# STM32WB55xx register map
File version: 1.0
Registers are 32-bit, read-write, reset 0x0 unless marked. A register's access mark holds for its fields unless they carry their own. Offsets are from the block's base; [hi:lo] are bit positions; {n}, {i} and the like mark numbered series; 'fields as' and 'values as' point back to an identical list.

## RCC — Reset and Clock Control
Base 0x58000000
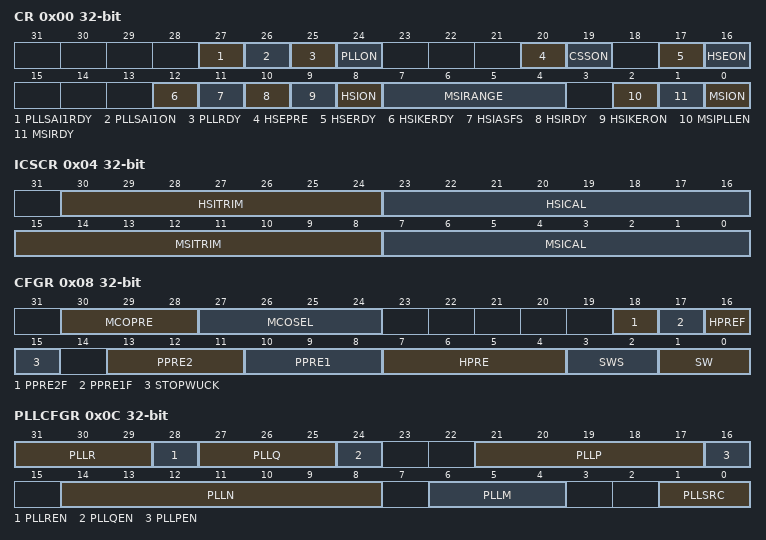
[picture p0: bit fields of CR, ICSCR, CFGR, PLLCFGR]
0x00 CR — RCC clock Control Register
  [27] PLLSAI1RDY — SAI1 PLL ready
  [26] PLLSAI1ON — SAI1 PLL enable
  [25] PLLRDY — System PLL clock ready
  [24] PLLON — System PLL clock enable
  [20] HSEPRE — HSE sysclk prescaler
  [19] CSSON — HSE Clock Security System enable
  [17] HSERDY — External High Speed oscillator (HSE) clock ready
  [16] HSEON — External High Speed oscillator (HSE) clock enable
  [12] HSIKERDY — Internal High Speed oscillator (HSI16) clock enable for some IPs Kernel ready flag
  [11] HSIASFS — HSI16 Automatic Start from Stop
  [10] HSIRDY — Internal High Speed oscillator (HSI16) clock ready flag
  [9] HSIKERON — Internal High Speed oscillator (HSI16) clock enable for some IPs Kernel
  [8] HSION — Internal High Speed oscillator (HSI16) clock enable
  [7:4] MSIRANGE — Internal Multi Speed oscillator (MSI) clock Range
    0=MSI = 100 KHz; 1=MSI = 200 KHz; 2=MSI = 400 KHz; 3=MSI = 800 KHz; 4=MSI = 1 MHz; 5=MSI = 2 MHz; 6=MSI = 4 MHz; 7=MSI = 8 MHz; 8=MSI = 16 MHz; 9=MSI = 24 MHz; 10=MSI = 32 MHz; 11=MSI = 48 MHz
  [2] MSIPLLEN — Internal Multi Speed oscillator (MSI) PLL enable
  [1] MSIRDY — Internal Multi Speed oscillator (MSI) clock ready flag
  [0] MSION — Internal Multi Speed oscillator (MSI) clock enable
0x04 ICSCR — RCC Internal Clock Sources Calibration Register
  [30:24] HSITRIM — HSITRIM[6:0] bits
  [23:16] HSICAL — HSICAL[7:0] bits
  [15:8] MSITRIM — MSITRIM[7:0] bits
  [7:0] MSICAL — MSICAL[7:0] bits
0x08 CFGR — RCC Clocks Configuration Register
  [30:28] MCOPRE — MCO prescaler
  [27:24] MCOSEL — MCOSEL [3:0] bits (Clock output selection)
  [18] PPRE2F — APB2 prescaler flag
  [17] PPRE1F — CPU1 APB1 prescaler flag
  [16] HPREF — AHB prescaler flag
  [15] STOPWUCK — Wake Up from stop and CSS backup clock selection
    0=MSI (MSI selection after wake-up from STOP); 1=HSI (HSI selection after wake-up from STOP)
  [13:11] PPRE2 — PRE2[2:0] bits (APB2 prescaler)
    0=DIV_1 (HCLK1 not divided); 4=DIV_2 (HCLK1 divided by 2); 5=DIV_4 (HCLK1 divided by 4); 6=DIV_8 (HCLK1 divided by 8); 7=DIV_16 (HCLK1 divided by 16)
  [10:8] PPRE1 — PRE1[2:0] bits (APB1 prescaler)
    values as PPRE2
  [7:4] HPRE — HPRE[3:0] bits (AHB prescaler)
    0=DIV_1 (SYSCLK not divided); 8=DIV_2 (SYSCLK divided by 2); 1=DIV_3 (SYSCLK divided by 3); 9=DIV_4 (SYSCLK divided by 4); 2=DIV_5 (SYSCLK divided by 5); 5=DIV_6 (SYSCLK divided by 6); 10=DIV_8 (SYSCLK divided by 8); 6=DIV_10 (SYSCLK divided by 10); 11=DIV_16 (SYSCLK divided by 16); 7=DIV_32 (SYSCLK divided by 32); 12=DIV_64 (SYSCLK divided by 64); 13=DIV_128 (SYSCLK divided by 128); 14=DIV_256 (SYSCLK divided by 256); 15=DIV_512 (SYSCLK divided by 512)
  [3:2] SWS — SWS[1:0] bits (System Clock Switch Status)
    0=MSI (MSI used as system clock); 1=HSI (HSI used as system clock); 2=HSE (HSE used as system clock); 3=PLL (PLL used as system clock)
  [1:0] SW — SW[1:0] bits (System clock Switch)
    0=MSI (MSI selection as system clock); 1=HSI (HSI selection as system clock); 2=HSE (HSE selection as system clock); 3=PLL (PLL selection as system clock)
0x0C PLLCFGR — RCC System PLL configuration Register
  [31:29] PLLR
    {v}=DIV_{v+1} (Main PLL division factor for PLLCLK (system clock) by {v+1}) (v=1..7)
  [28] PLLREN
  [27:25] PLLQ
    {v}=DIV_{v+1} (Main PLL division factor for PLLQ output by {v+1}) (v=1..7)
  [24] PLLQEN
  [21:17] PLLP
    {v}=DIV_{v+1} (Main PLL division factor for PLLP output by {v+1}) (v=1..31)
  [16] PLLPEN
  [14:8] PLLN
  [6:4] PLLM
    {v}=DIV_{v+1} (PLL and PLLSAI1 division factor by {v+1}) (v=0..7)
  [1:0] PLLSRC
    1=MSI (MSI clock selected as PLL entry clock source); 2=HSI (HSI clock selected as PLL entry clock source); 3=HSE (HSE clock selected as PLL entry clock source); 0=NONE (No clock)
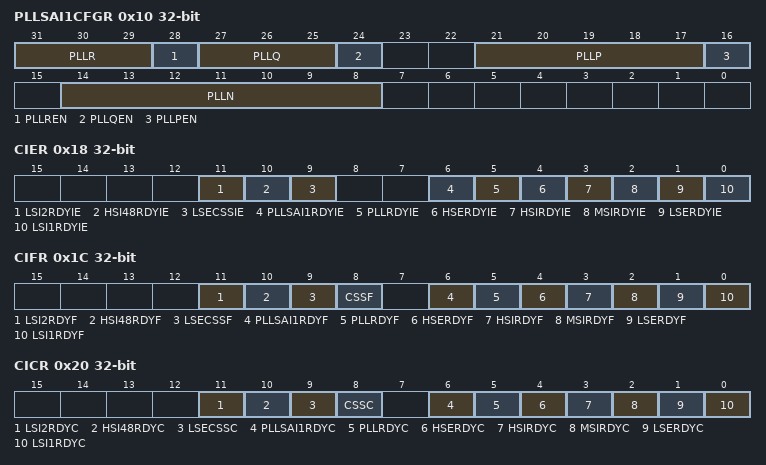
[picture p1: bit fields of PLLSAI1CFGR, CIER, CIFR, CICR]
0x10 PLLSAI1CFGR — RCC PLL SAI1 configuration Register
  [31:29] PLLR
    {v}=DIV_{v+1} (PLLSAI1 division factor for PLLSAI1R output by {v+1}) (v=1..7)
  [28] PLLREN
  [27:25] PLLQ
    {v}=DIV_{v+1} (PLLSAI1 division factor for PLLSAI1Q output by {v+1}) (v=1..7)
  [24] PLLQEN
  [21:17] PLLP
    values as PLLCFGR.PLLP
  [16] PLLPEN
  [14:8] PLLN
0x18 CIER — RCC Clock Interrupt Enable Register
  [11] LSI2RDYIE, [10] HSI48RDYIE, [9] LSECSSIE, [6] PLLSAI1RDYIE, [5] PLLRDYIE, [4] HSERDYIE, [3] HSIRDYIE, [2] MSIRDYIE, [1] LSERDYIE, [0] LSI1RDYIE
0x1C CIFR — RCC Clock Interrupt Flag Register
  [11] LSI2RDYF, [10] HSI48RDYF, [9] LSECSSF, [8] CSSF, [6] PLLSAI1RDYF, [5] PLLRDYF, [4] HSERDYF, [3] HSIRDYF, [2] MSIRDYF, [1] LSERDYF, [0] LSI1RDYF
0x20 CICR — RCC Clock Interrupt Clear Register
  [11] LSI2RDYC, [10] HSI48RDYC, [9] LSECSSC, [8] CSSC, [6] PLLSAI1RDYC, [5] PLLRDYC, [4] HSERDYC, [3] HSIRDYC, [2] MSIRDYC, [1] LSERDYC, [0] LSI1RDYC
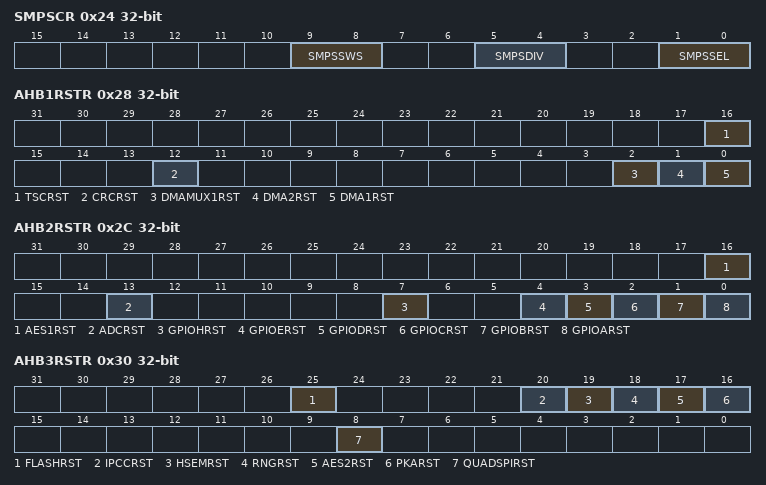
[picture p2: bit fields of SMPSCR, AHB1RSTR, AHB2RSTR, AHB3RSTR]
0x24 SMPSCR — RCC SMPS step-down converter control register
  [9:8] SMPSSWS
    0=HSI (HSI used as SMPS clock); 1=MSI (MSI used as SMPS clock); 2=HSE (HSE used as SMPS clock); 3=NO_CLOCK (No Clock used as SMPS clock)
  [5:4] SMPSDIV
    {v}=DIV_{v} (SMPS clock division {v}) (v=0..3)
  [1:0] SMPSSEL
    0=HSI (HSI selection as SMPS clock); 1=MSI (MSI selection as SMPS clock); 2=HSE (HSE selection as SMPS clock)
0x28 AHB1RSTR — RCC AHB1 peripheral reset register
  [16] TSCRST, [12] CRCRST, [2] DMAMUX1RST, [1] DMA2RST, [0] DMA1RST
0x2C AHB2RSTR — RCC AHB2 peripheral reset register
  [16] AES1RST, [13] ADCRST, [7] GPIOHRST, [4] GPIOERST, [3] GPIODRST, [2] GPIOCRST, [1] GPIOBRST, [0] GPIOARST
0x30 AHB3RSTR — RCC AHB3 & AHB4 peripheral reset register
  [25] FLASHRST, [20] IPCCRST, [19] HSEMRST, [18] RNGRST, [17] AES2RST, [16] PKARST, [8] QUADSPIRST
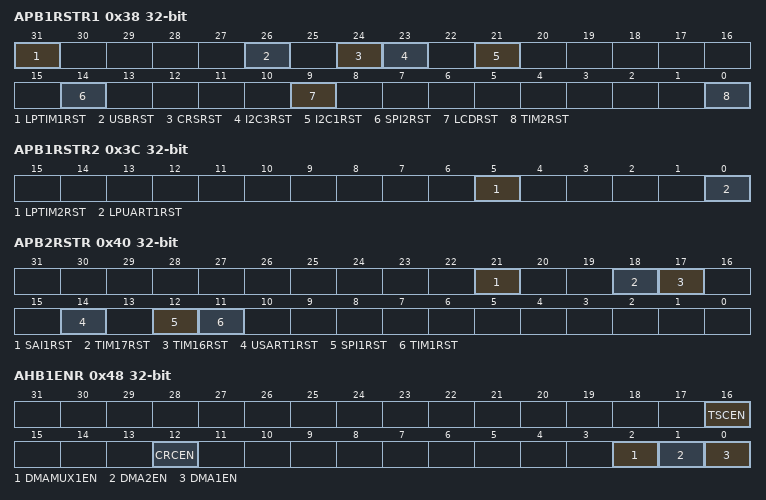
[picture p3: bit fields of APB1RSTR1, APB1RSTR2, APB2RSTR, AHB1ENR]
0x38 APB1RSTR1 — RCC APB1 peripheral reset register 1
  [31] LPTIM1RST, [26] USBRST, [24] CRSRST, [23] I2C3RST, [21] I2C1RST, [14] SPI2RST, [9] LCDRST, [0] TIM2RST
0x3C APB1RSTR2 — RCC APB1 peripheral reset register 2
  [5] LPTIM2RST, [0] LPUART1RST
0x40 APB2RSTR — RCC APB2 peripheral reset register
  [21] SAI1RST, [18] TIM17RST, [17] TIM16RST, [14] USART1RST, [12] SPI1RST, [11] TIM1RST
0x44 APB3RSTR — RCC APB3 peripheral reset register
  [0] RFRST
0x48 AHB1ENR — RCC AHB1 peripheral clocks enable register
  [16] TSCEN, [12] CRCEN, [2] DMAMUX1EN, [1] DMA2EN, [0] DMA1EN
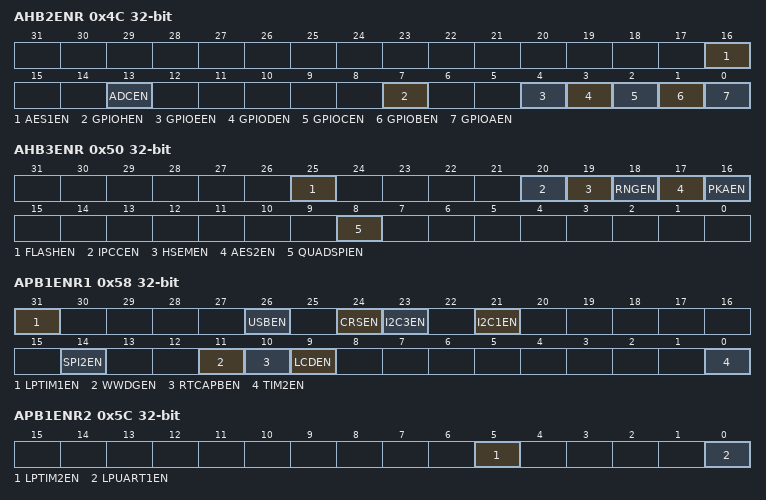
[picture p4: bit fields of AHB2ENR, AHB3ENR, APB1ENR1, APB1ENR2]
0x4C AHB2ENR — RCC AHB2 peripheral clocks enable register
  [16] AES1EN, [13] ADCEN, [7] GPIOHEN, [4] GPIOEEN, [3] GPIODEN, [2] GPIOCEN, [1] GPIOBEN, [0] GPIOAEN
0x50 AHB3ENR — RCC AHB3 & AHB4 peripheral clocks enable register
  [25] FLASHEN, [20] IPCCEN, [19] HSEMEN, [18] RNGEN, [17] AES2EN, [16] PKAEN, [8] QUADSPIEN
0x58 APB1ENR1 — RCC APB1 peripheral clocks enable register 1
  [31] LPTIM1EN, [26] USBEN, [24] CRSEN, [23] I2C3EN, [21] I2C1EN, [14] SPI2EN, [11] WWDGEN, [10] RTCAPBEN, [9] LCDEN, [0] TIM2EN
0x5C APB1ENR2 — RCC APB1 peripheral clocks enable register 2
  [5] LPTIM2EN, [0] LPUART1EN
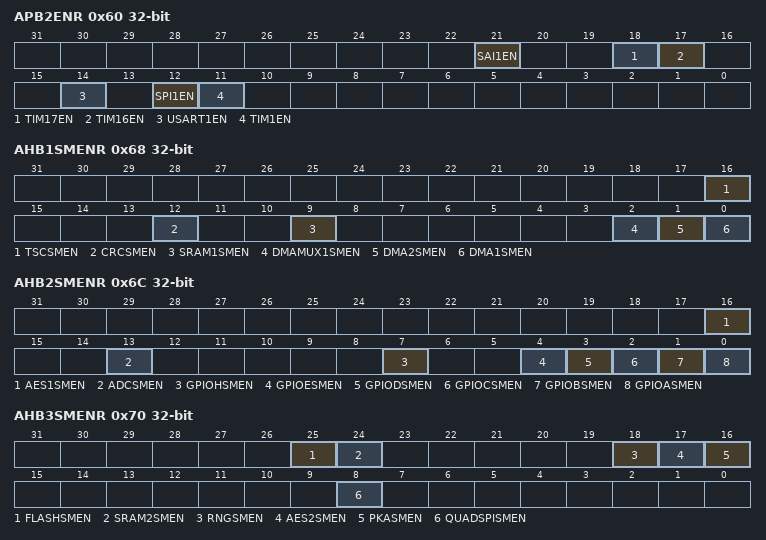
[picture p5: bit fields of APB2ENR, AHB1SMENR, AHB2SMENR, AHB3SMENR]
0x60 APB2ENR — RCC APB2 peripheral clocks enable register
  [21] SAI1EN, [18] TIM17EN, [17] TIM16EN, [14] USART1EN, [12] SPI1EN, [11] TIM1EN
0x68 AHB1SMENR — RCC AHB1 peripheral clocks enable in sleep and stop modes register
  [16] TSCSMEN, [12] CRCSMEN, [9] SRAM1SMEN, [2] DMAMUX1SMEN, [1] DMA2SMEN, [0] DMA1SMEN
0x6C AHB2SMENR — RCC AHB2 peripheral clocks enable in sleep and stop modes register
  [16] AES1SMEN, [13] ADCSMEN, [7] GPIOHSMEN, [4] GPIOESMEN, [3] GPIODSMEN, [2] GPIOCSMEN, [1] GPIOBSMEN, [0] GPIOASMEN
0x70 AHB3SMENR — RCC AHB3 & AHB4 peripheral clocks enable in sleep and stop modes register
  [25] FLASHSMEN, [24] SRAM2SMEN, [18] RNGSMEN, [17] AES2SMEN, [16] PKASMEN, [8] QUADSPISMEN
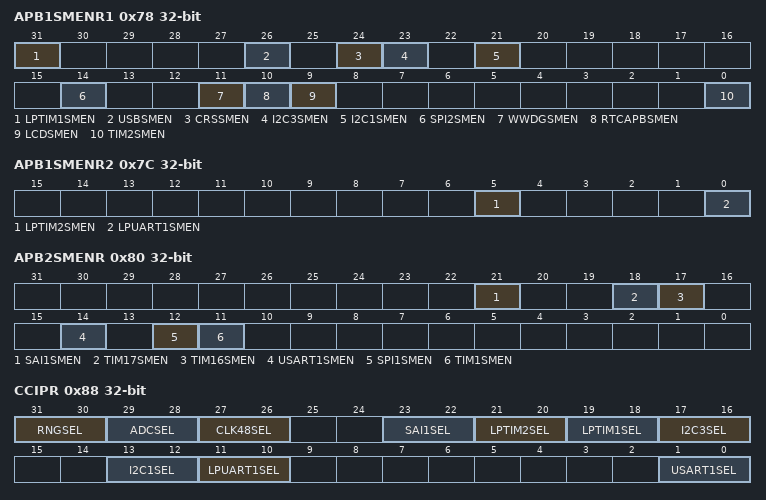
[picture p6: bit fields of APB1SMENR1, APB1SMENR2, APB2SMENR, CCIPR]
0x78 APB1SMENR1 — RCC APB1 peripheral clocks enable in sleep mode and stop modes register 1
  [31] LPTIM1SMEN, [26] USBSMEN, [24] CRSSMEN, [23] I2C3SMEN, [21] I2C1SMEN, [14] SPI2SMEN, [11] WWDGSMEN, [10] RTCAPBSMEN, [9] LCDSMEN, [0] TIM2SMEN
0x7C APB1SMENR2 — RCC APB1 peripheral clocks enable in sleep mode and stop modes register 2
  [5] LPTIM2SMEN, [0] LPUART1SMEN
0x80 APB2SMENR — RCC APB2 peripheral clocks enable in sleep mode and stop modes register
  [21] SAI1SMEN, [18] TIM17SMEN, [17] TIM16SMEN, [14] USART1SMEN, [12] SPI1SMEN, [11] TIM1SMEN
0x88 CCIPR — RCC Peripherals Clock Configuration Independent Register
  [31:30] RNGSEL
    0=CLK48 (CLK48 divided by 3 selected as RNG Clock); 1=LSI (LSI selected as ADC clock); 2=LSE (LSE selected as ADC clock)
  [29:28] ADCSEL
    0=NONE (no Clock used as ADC clock); 1=PLLSAI1 (PLLSAI1 selected as ADC clock); 2=PLL (PLL selected as ADC clock); 3=SYSCLK (SYSCLK selected as ADC clock)
  [27:26] CLK48SEL
    0=HSI48 (HSI48 selected as CLK48 clock); 1=PLLSAI1 (PLLSAI1 selected as CLK48 clock); 2=PLL (PLL selected as CLK48 clock); 3=MSI (MSI selected as CLK48 clock)
  [23:22] SAI1SEL
    0=PLLSAI1 (PLLSAI1 selected as SAI1 clock); 1=PLL (PLL selected as SAI1 clock); 2=HSI (HSI selected as SAI1 clock); 3=PIN (External input selected as SAI1 clock)
  [21:20] LPTIM2SEL
  [19:18] LPTIM1SEL
  [17:16] I2C3SEL
  [13:12] I2C1SEL
  [11:10] LPUART1SEL
    0=PCLK1 (PCLK1 selected as LPUART1 clock); 1=SYSCLK (SYCLK selected as LPUART1 clock); 2=HSI (HSI selected as LPUART1 clock); 3=LSE (LSE selected as LPUART1 clock)
  [1:0] USART1SEL
    0=PCLK2 (PCLK2 selected as USART1 clock); 1=SYSCLK (SYSCLK selected as USART1 clock); 2=HSI (HSI selected as USART1 clock); 3=LSE (LSE selected as USART1 clock)
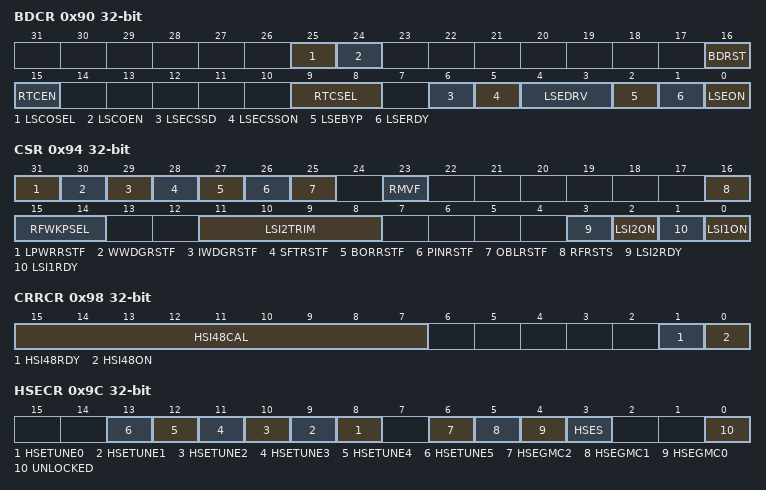
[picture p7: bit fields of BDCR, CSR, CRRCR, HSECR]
0x90 BDCR — RCC Backup Domain Control Register
  [25] LSCOSEL
    0=LSI (LSI selection for low speed clock); 1=LSE (LSE selection for low speed clock)
  [24] LSCOEN
  [16] BDRST
  [15] RTCEN
  [9:8] RTCSEL
    0=NONE (No clock used as RTC clock); 1=LSE (LSE oscillator clock used as RTC clock); 2=LSI (LSI oscillator clock used as RTC clock); 3=HSE_DIV32 (HSE oscillator clock divided by 32 used as RTC clock)
  [6] LSECSSD
  [5] LSECSSON
  [4:3] LSEDRV
    0=LOW (Xtal mode lower driving capability); 1=MEDIUMLOW (Xtal mode medium low driving capability); 2=MEDIUMHIGH (Xtal mode medium high driving capability); 3=HIGH (Xtal mode higher driving capability)
  [2] LSEBYP
  [1] LSERDY
  [0] LSEON
0x94 CSR — RCC Control and Status Register
  [31] LPWRRSTF
  [30] WWDGRSTF
  [29] IWDGRSTF
  [28] SFTRSTF
  [27] BORRSTF
  [26] PINRSTF
  [25] OBLRSTF
  [23] RMVF
  [16] RFRSTS
  [15:14] RFWKPSEL
    0=NONE (No clock used as RF Wakeup clock); 1=LSE (LSE oscillator clock used as RF Wakeup clock); 3=HSE_DIV1024 (HSE oscillator clock divided by 1024 used as RF Wakeup clock)
  [11:8] LSI2TRIM
  [3] LSI2RDY
  [2] LSI2ON
  [1] LSI1RDY
  [0] LSI1ON
0x98 CRRCR — RCC Clock Recovery RC Register
  [15:7] HSI48CAL, [1] HSI48RDY, [0] HSI48ON
0x9C HSECR — RCC HSE Clock Register
  [n+8] HSETUNE{n} (n=0..5)
  [6] HSEGMC2
  [5] HSEGMC1
  [4] HSEGMC0
  [3] HSES
    0=HSEAMPTHRESHOLD_1_2 (HSE sense amplifier bias current factor = 1/2); 1=HSEAMPTHRESHOLD_3_4 (HSE sense amplifier bias current factor = 3/4)
  [0] UNLOCKED
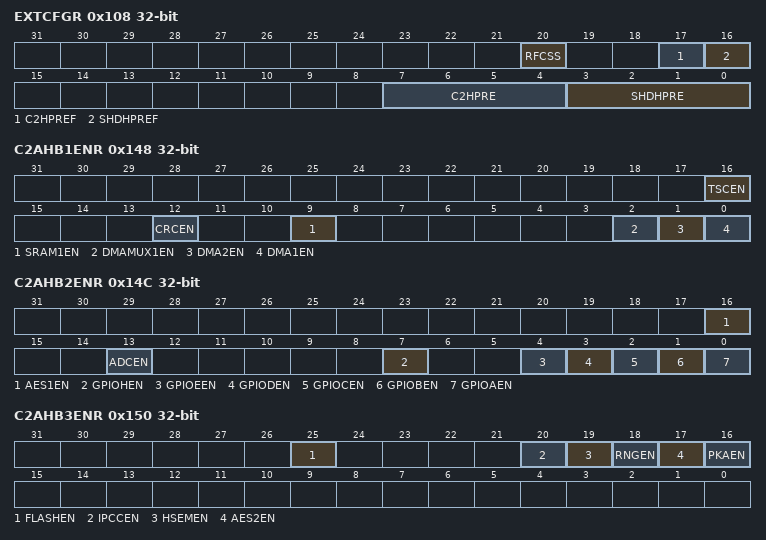
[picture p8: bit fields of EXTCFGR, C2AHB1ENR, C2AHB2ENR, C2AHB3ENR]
0x108 EXTCFGR — RCC Extended Clock Recovery Register
  [20] RFCSS
    0=HSI (HSI used as RF system clock); 1=HSE_DIV2 (HSE divided by 2 used as RF system clock)
  [17] C2HPREF
  [16] SHDHPREF
  [7:4] C2HPRE
    values as CFGR.HPRE
  [3:0] SHDHPRE
0x148 C2AHB1ENR — RRCC AHB1 peripheral CPU2 clocks enable register
  [16] TSCEN, [12] CRCEN, [9] SRAM1EN, [2] DMAMUX1EN, [1] DMA2EN, [0] DMA1EN
0x14C C2AHB2ENR — RCC AHB2 peripheral CPU2 clocks enable register
  fields as AHB2ENR
0x150 C2AHB3ENR — RCC AHB3 & AHB4 peripheral CPU2 clocks enable register
  [25] FLASHEN, [20] IPCCEN, [19] HSEMEN, [18] RNGEN, [17] AES2EN, [16] PKAEN
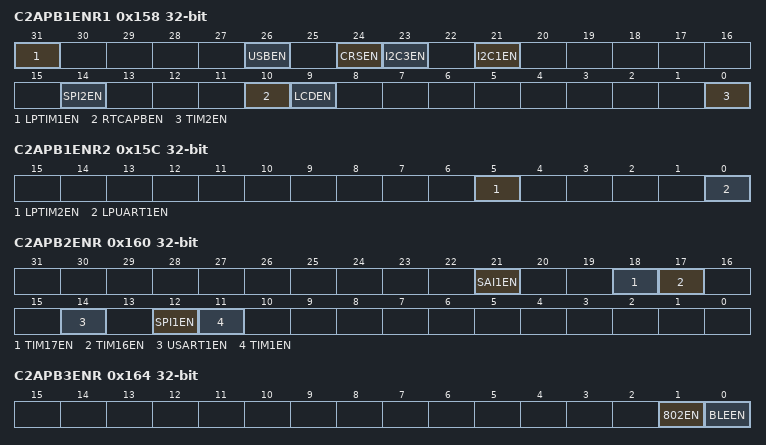
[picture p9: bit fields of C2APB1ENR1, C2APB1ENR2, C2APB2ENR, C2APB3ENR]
0x158 C2APB1ENR1 — RCC APB1 peripheral CPU2 clocks enable register 1
  [31] LPTIM1EN, [26] USBEN, [24] CRSEN, [23] I2C3EN, [21] I2C1EN, [14] SPI2EN, [10] RTCAPBEN, [9] LCDEN, [0] TIM2EN
0x15C C2APB1ENR2 — RCC APB1 peripheral CPU2 clocks enable register 2
  [5] LPTIM2EN, [0] LPUART1EN
0x160 C2APB2ENR — RCC APB2 peripheral CPU2 clocks enable register 1
  fields as APB2ENR
0x164 C2APB3ENR — RCC APB3 peripheral CPU2 clocks enable register 1
  [1] 802EN, [0] BLEEN
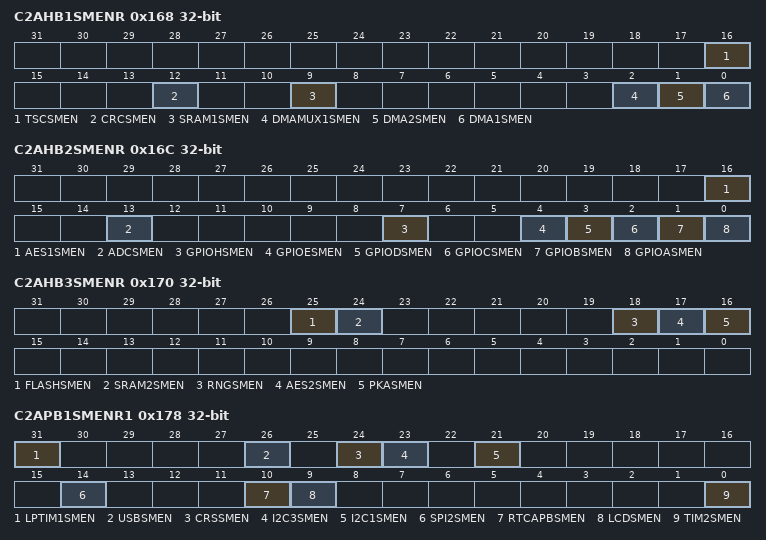
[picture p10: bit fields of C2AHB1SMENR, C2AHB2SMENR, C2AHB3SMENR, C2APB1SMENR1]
0x168 C2AHB1SMENR — RCC AHB1 peripheral CPU2 clocks enable in sleep and stop modes register
  fields as AHB1SMENR
0x16C C2AHB2SMENR — RCC AHB2 peripheral CPU2 clocks enable in sleep and stop modes register
  fields as AHB2SMENR
0x170 C2AHB3SMENR — RCC AHB3 & AHB4 peripheral CPU2 clocks enable in sleep and stop modes register
  [25] FLASHSMEN, [24] SRAM2SMEN, [18] RNGSMEN, [17] AES2SMEN, [16] PKASMEN
0x178 C2APB1SMENR1 — RCC APB1 peripheral CPU2 clocks enable in sleep mode and stop modes register 1
  [31] LPTIM1SMEN, [26] USBSMEN, [24] CRSSMEN, [23] I2C3SMEN, [21] I2C1SMEN, [14] SPI2SMEN, [10] RTCAPBSMEN, [9] LCDSMEN, [0] TIM2SMEN
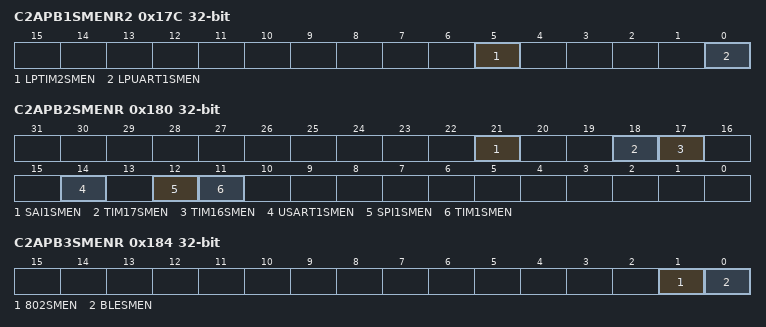
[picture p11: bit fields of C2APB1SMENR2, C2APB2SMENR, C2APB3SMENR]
0x17C C2APB1SMENR2 — RCC APB1 peripheral CPU2 clocks enable in sleep mode and stop modes register 2
  [5] LPTIM2SMEN, [0] LPUART1SMEN
0x180 C2APB2SMENR — RCC APB2 peripheral CPU2 clocks enable in sleep mode and stop modes register
  fields as APB2SMENR
0x184 C2APB3SMENR — RCC APB3 peripheral CPU2 clocks enable in sleep mode and stop modes register
  [1] 802SMEN, [0] BLESMEN
